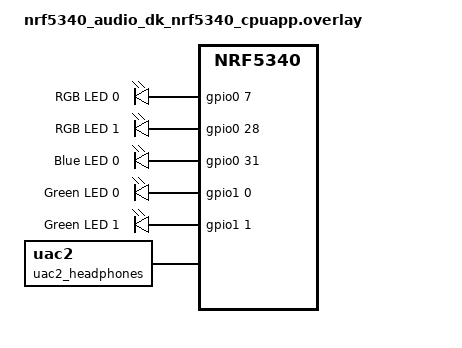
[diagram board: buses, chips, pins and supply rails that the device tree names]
/*
 * Copyright (c) 2025 Nordic Semiconductor ASA
 *
 * SPDX-License-Identifier: LicenseRef-Nordic-5-Clause
 */

#include <dt-bindings/led/led.h>
#include <dt-bindings/usb/audio.h>

/ {
	audioleds: audioleds {
		compatible = "gpio-leds";
		status = "okay";

		led_device_type: led_device_type {
			gpios = <&gpio0 7 GPIO_ACTIVE_HIGH>,
				<&gpio0 25 GPIO_ACTIVE_HIGH>,
				<&gpio0 26 GPIO_ACTIVE_HIGH>;
			label = "RGB LED 0";
		};

		rgb2: rgb-2 {
			gpios = <&gpio0 28 GPIO_ACTIVE_HIGH>,
				<&gpio0 29 GPIO_ACTIVE_HIGH>,
				<&gpio0 30 GPIO_ACTIVE_HIGH>;
			label = "RGB LED 1";
		};

		led_conn_status: led_conn_status {
			gpios = <&gpio0 31 GPIO_ACTIVE_HIGH>;
			label = "Blue LED 0";
		};

		led_sync_status: led_sync_status {
			gpios = <&gpio1 0 GPIO_ACTIVE_HIGH>;
			label = "Green LED 0";
		};

		led_app_status: led_app_status {
			gpios = <&gpio1 1 GPIO_ACTIVE_HIGH>;
			label = "Green LED 1";
		};
	};
};

/ {
	uac2_headphones: usb_audio2 {
		compatible = "zephyr,uac2";
		status = "okay";
		full-speed;
		audio-function = <AUDIO_FUNCTION_OTHER>;

		hp_uac_aclk: hp_aclk {
			compatible = "zephyr,uac2-clock-source";
			clock-type = "internal-programmable";
			frequency-control = "read-only";
			sampling-frequencies = <48000>;
		};

		hp_out_terminal: out_terminal {
			compatible = "zephyr,uac2-input-terminal";
			clock-source = <&hp_uac_aclk>;
			terminal-type = <USB_TERMINAL_STREAMING>;
			front-left;
			front-right;
		};

		hp_headphones_output: hp_headphones_output {
			compatible = "zephyr,uac2-output-terminal";
			data-source = <&hp_out_terminal>;
			clock-source = <&hp_uac_aclk>;
			terminal-type = <OUTPUT_TERMINAL_HEADPHONES>;
		};

		hp_as_iso_out: out_interface {
			compatible = "zephyr,uac2-audio-streaming";
			linked-terminal = <&hp_out_terminal>;
			subslot-size = <2>;
			bit-resolution = <16>;
		};
	};
};
